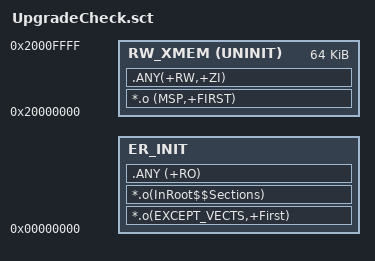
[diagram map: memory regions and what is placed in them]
; *****************************************************************************
; *** Scatter-Loading Description File generated by uVision & modify by user***
; *****************************************************************************

LR_FLASH 0x00000000 0x800000 - 255 * 1024 {;load region size_region
	ER_INIT 0x00000000  {;execution address = load addressCallTree
		*.o(EXCEPT_VECTS,+First)
		*.o(InRoot$$Sections)
		.ANY (+RO)
	}

	;do not change the execution region name named RW_XMEM
	;you can enlarge or shrink the region size as you want
	RW_XMEM 0x20000000 UNINIT 0x10000 {;64KB XMEM
		*.o (MSP,+FIRST)
		.ANY(+RW,+ZI)
	}

	;you can delete the following two execute regions if you
	;want to use the whole memory totally
;	RW_VMEM 0x20010000 UNINIT 0x8000  {;32KB VMEM
; 	}

;	RW_PMEM 0x20018000 UNINIT 0x8000 {;32KB PMEM
;	}
}

